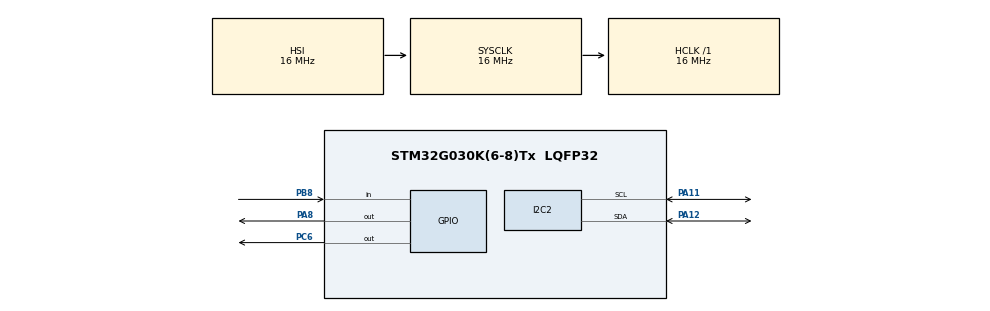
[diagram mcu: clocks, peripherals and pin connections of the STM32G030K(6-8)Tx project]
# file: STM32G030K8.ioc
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I2C2.Timing=0x00503D58
Mcu.Family=STM32G0
Mcu.Name=STM32G030K(6-8)Tx
Mcu.Package=LQFP32
PA10.Signal=USART1_RX
PA11\ [PA9].Mode=I2C
PA11\ [PA9].Signal=I2C2_SCL
PA12\ [PA10].Mode=I2C
PA12\ [PA10].Signal=I2C2_SDA
PA13.Mode=Serial_Wire
PA13.Signal=SYS_SWDIO
PA14-BOOT0.Mode=Serial_Wire
PA14-BOOT0.Signal=SYS_SWCLK
PA2.Signal=USART2_TX
PA3.Signal=USART2_RX
PA8.Signal=GPIO_Output
PA9.Signal=USART1_TX
PB8.Signal=GPIO_Input
PC6.Signal=GPIO_Output
ProjectManager.HeapSize=0x200
ProjectManager.StackSize=0x400
ProjectManager.TargetToolchain=CMake
RCC.AHBFreq_Value=16000000
RCC.CortexFreq_Value=16000000
RCC.EXTERNAL_CLOCK_VALUE=12288000
RCC.HCLKFreq_Value=16000000
RCC.HSE_VALUE=8000000
RCC.HSI_VALUE=16000000
RCC.SYSCLKFreq_VALUE=16000000
RCC.VCOOutputFreq_Value=128000000
board=custom

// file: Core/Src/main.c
/* USER CODE BEGIN Header */
/**
  ******************************************************************************
  * @file           : main.c
  * @brief          : Main program body
  ******************************************************************************
  * @attention
  *
  * Copyright (c) 2026 STMicroelectronics.
  * All rights reserved.
  *
  * This software is licensed under terms that can be found in the LICENSE file
  * in the root directory of this software component.
  * If no LICENSE file comes with this software, it is provided AS-IS.
  *
  ******************************************************************************
  */
/* USER CODE END Header */
#include "main.h"
#include "app_main.h"

I2C_HandleTypeDef hi2c2;

void SystemClock_Config(void);
static void MX_GPIO_Init(void);
static void MX_I2C2_Init(void);

int main(void)
{

  /* MCU Configuration--------------------------------------------------------*/

  /* Reset of all peripherals, Initializes the Flash interface and the Systick. */
  HAL_Init();

  /* Configure the system clock */
  SystemClock_Config();

  /* Initialize all configured peripherals */
  MX_GPIO_Init();
  MX_I2C2_Init();
  /* USER CODE BEGIN 2 */
  app_init();

  /* USER CODE END 2 */

  /* Infinite loop */
  while (1)
  {

    /* USER CODE BEGIN 3 */
    app_main();
  }
  /* USER CODE END 3 */
}

void SystemClock_Config(void)
{
  RCC_OscInitTypeDef RCC_OscInitStruct = {0};
  RCC_ClkInitTypeDef RCC_ClkInitStruct = {0};

  /** Configure the main internal regulator output voltage
  */
  HAL_PWREx_ControlVoltageScaling(PWR_REGULATOR_VOLTAGE_SCALE1);

  /** Initializes the RCC Oscillators according to the specified parameters
  * in the RCC_OscInitTypeDef structure.
  */
  RCC_OscInitStruct.OscillatorType = RCC_OSCILLATORTYPE_HSI;
  RCC_OscInitStruct.HSIState = RCC_HSI_ON;
  RCC_OscInitStruct.HSIDiv = RCC_HSI_DIV1;
  RCC_OscInitStruct.HSICalibrationValue = RCC_HSICALIBRATION_DEFAULT;
  RCC_OscInitStruct.PLL.PLLState = RCC_PLL_NONE;
  if (HAL_RCC_OscConfig(&RCC_OscInitStruct) != HAL_OK)
  {
    Error_Handler();
  }

  /** Initializes the CPU, AHB and APB buses clocks
  */
  RCC_ClkInitStruct.ClockType = RCC_CLOCKTYPE_HCLK|RCC_CLOCKTYPE_SYSCLK
                              |RCC_CLOCKTYPE_PCLK1;
  RCC_ClkInitStruct.SYSCLKSource = RCC_SYSCLKSOURCE_HSI;
  RCC_ClkInitStruct.AHBCLKDivider = RCC_SYSCLK_DIV1;
  RCC_ClkInitStruct.APB1CLKDivider = RCC_HCLK_DIV1;

  if (HAL_RCC_ClockConfig(&RCC_ClkInitStruct, FLASH_LATENCY_0) != HAL_OK)
  {
    Error_Handler();
  }
}

static void MX_I2C2_Init(void)
{

  hi2c2.Instance = I2C2;
  hi2c2.Init.Timing = 0x00503D58;
  hi2c2.Init.OwnAddress1 = 0;
  hi2c2.Init.AddressingMode = I2C_ADDRESSINGMODE_7BIT;
  hi2c2.Init.DualAddressMode = I2C_DUALADDRESS_DISABLE;
  hi2c2.Init.OwnAddress2 = 0;
  hi2c2.Init.OwnAddress2Masks = I2C_OA2_NOMASK;
  hi2c2.Init.GeneralCallMode = I2C_GENERALCALL_DISABLE;
  hi2c2.Init.NoStretchMode = I2C_NOSTRETCH_DISABLE;
  if (HAL_I2C_Init(&hi2c2) != HAL_OK)
  {
    Error_Handler();
  }

  /** Configure Analogue filter
  */
  if (HAL_I2CEx_ConfigAnalogFilter(&hi2c2, I2C_ANALOGFILTER_ENABLE) != HAL_OK)
  {
    Error_Handler();
  }

  /** Configure Digital filter
  */
  if (HAL_I2CEx_ConfigDigitalFilter(&hi2c2, 0) != HAL_OK)
  {
    Error_Handler();
  }

}

static void MX_GPIO_Init(void)
{
  GPIO_InitTypeDef GPIO_InitStruct = {0};

  /* GPIO Ports Clock Enable */
  __HAL_RCC_GPIOA_CLK_ENABLE();
  __HAL_RCC_GPIOC_CLK_ENABLE();
  __HAL_RCC_GPIOB_CLK_ENABLE();

  /*Configure GPIO pin Output Level */
  HAL_GPIO_WritePin(GPIOA, GPIO_PIN_8, GPIO_PIN_RESET);

  /*Configure GPIO pin Output Level */
  HAL_GPIO_WritePin(GPIOC, GPIO_PIN_6, GPIO_PIN_RESET);

  /*Configure GPIO pins : PA2 PA3 */
  GPIO_InitStruct.Pin = GPIO_PIN_2|GPIO_PIN_3;
  GPIO_InitStruct.Mode = GPIO_MODE_AF_PP;
  GPIO_InitStruct.Pull = GPIO_NOPULL;
  GPIO_InitStruct.Speed = GPIO_SPEED_FREQ_LOW;
  GPIO_InitStruct.Alternate = GPIO_AF1_USART2;
  HAL_GPIO_Init(GPIOA, &GPIO_InitStruct);

  /*Configure GPIO pin : PA8 */
  GPIO_InitStruct.Pin = GPIO_PIN_8;
  GPIO_InitStruct.Mode = GPIO_MODE_OUTPUT_PP;
  GPIO_InitStruct.Pull = GPIO_NOPULL;
  GPIO_InitStruct.Speed = GPIO_SPEED_FREQ_LOW;
  HAL_GPIO_Init(GPIOA, &GPIO_InitStruct);

  /*Configure GPIO pins : PA9 PA10 */
  GPIO_InitStruct.Pin = GPIO_PIN_9|GPIO_PIN_10;
  GPIO_InitStruct.Mode = GPIO_MODE_AF_PP;
  GPIO_InitStruct.Pull = GPIO_NOPULL;
  GPIO_InitStruct.Speed = GPIO_SPEED_FREQ_LOW;
  GPIO_InitStruct.Alternate = GPIO_AF1_USART1;
  HAL_GPIO_Init(GPIOA, &GPIO_InitStruct);

  /*Configure GPIO pin : PC6 */
  GPIO_InitStruct.Pin = GPIO_PIN_6;
  GPIO_InitStruct.Mode = GPIO_MODE_OUTPUT_PP;
  GPIO_InitStruct.Pull = GPIO_NOPULL;
  GPIO_InitStruct.Speed = GPIO_SPEED_FREQ_LOW;
  HAL_GPIO_Init(GPIOC, &GPIO_InitStruct);

  /*Configure GPIO pin : PB8 */
  GPIO_InitStruct.Pin = GPIO_PIN_8;
  GPIO_InitStruct.Mode = GPIO_MODE_INPUT;
  GPIO_InitStruct.Pull = GPIO_NOPULL;
  HAL_GPIO_Init(GPIOB, &GPIO_InitStruct);

}

void Error_Handler(void)
{
  __disable_irq();
  while (1)
  {
  }
}
